# DMPAC0_DOF_0_PAR_DOF_CFG_VP_MEM_MMRRAM_VBUSP_MMR_RAM register map
Vendor: Texas Instruments
Peripheral module from a debugger description file (folder J7_AHP).
Registers are 32-bit, read-only, reset 0x0 unless marked. A register's access mark holds for its fields unless they carry their own. Offsets are as the file gives them; lines under a group give offsets from that group; [hi:lo] are bit positions; {n}, {i} and the like mark numbered series; 'fields as' and 'values as' point back to an identical list; <NAME> marks a mode.

## DMPAC0_DOF_0_PAR_DOF_CFG_VP_MEM_MMRRAM_VBUSP_MMR_RAM
0x00 PAR_DOF__CFG_VP__MEM_MMR__MMRRAM_VBUSP__MMR_RAM_PSE_MEM_RAM
  [31:0] DATA — Data read from RAM. RAM is wider than 32bit vbus. MMR reads are byte addresses into RAM where RAM Width is extended/zero padded to next pwr2.
{0x2000+0x2000*i} PAR_DOF__CFG_VP__MEM_MMR__MMRRAM_VBUSP__MMR_RAM_SRB_MEM{i}_RAM (i=0..15)
  fields as PAR_DOF__CFG_VP__MEM_MMR__MMRRAM_VBUSP__MMR_RAM_PSE_MEM_RAM
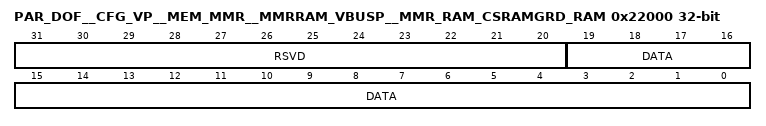
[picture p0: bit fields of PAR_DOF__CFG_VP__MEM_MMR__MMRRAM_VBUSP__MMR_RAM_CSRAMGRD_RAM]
0x22000 PAR_DOF__CFG_VP__MEM_MMR__MMRRAM_VBUSP__MMR_RAM_CSRAMGRD_RAM
  [31:20] RSVD — Always read as 0. Writes have no effect.
  [19:0] DATA — Data read from RAM
0x24000 PAR_DOF__CFG_VP__MEM_MMR__MMRRAM_VBUSP__MMR_RAM_CSRAMIIR_RAM
  fields as PAR_DOF__CFG_VP__MEM_MMR__MMRRAM_VBUSP__MMR_RAM_PSE_MEM_RAM
0x28000 PAR_DOF__CFG_VP__MEM_MMR__MMRRAM_VBUSP__MMR_RAM_MFRAM0_RAM
  fields as PAR_DOF__CFG_VP__MEM_MMR__MMRRAM_VBUSP__MMR_RAM_PSE_MEM_RAM
0x2C000 PAR_DOF__CFG_VP__MEM_MMR__MMRRAM_VBUSP__MMR_RAM_MFRAM1_RAM
  fields as PAR_DOF__CFG_VP__MEM_MMR__MMRRAM_VBUSP__MMR_RAM_PSE_MEM_RAM
